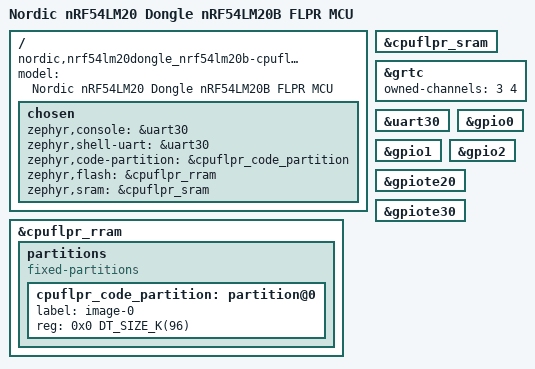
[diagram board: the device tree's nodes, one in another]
/*
 * Copyright (c) 2026 Nordic Semiconductor ASA
 *
 * SPDX-License-Identifier: LicenseRef-Nordic-5-Clause
 */

/dts-v1/;
#include <nordic/nrf54lm20b_cpuflpr.dtsi>
#include "nrf54lm20dongle_nrf54lm20b-common.dtsi"

/ {
	model = "Nordic nRF54LM20 Dongle nRF54LM20B FLPR MCU";
	compatible = "nordic,nrf54lm20dongle_nrf54lm20b-cpuflpr";

	chosen {
		zephyr,console = &uart30;
		zephyr,shell-uart = &uart30;
		zephyr,code-partition = &cpuflpr_code_partition;
		zephyr,flash = &cpuflpr_rram;
		zephyr,sram = &cpuflpr_sram;
	};
};

&cpuflpr_sram {
	status = "okay";
};

&cpuflpr_rram {
	partitions {
		compatible = "fixed-partitions";
		#address-cells = <1>;
		#size-cells = <1>;

		cpuflpr_code_partition: partition@0 {
			label = "image-0";
			reg = <0x0 DT_SIZE_K(96)>;
		};
	};
};

&grtc {
	owned-channels = <3 4>;
	status = "okay";
};

&uart30 {
	status = "okay";
};

&gpio0 {
	status = "okay";
};

&gpio1 {
	status = "okay";
};

&gpio2 {
	status = "okay";
};

&gpiote20 {
	status = "okay";
};

&gpiote30 {
	status = "okay";
};
